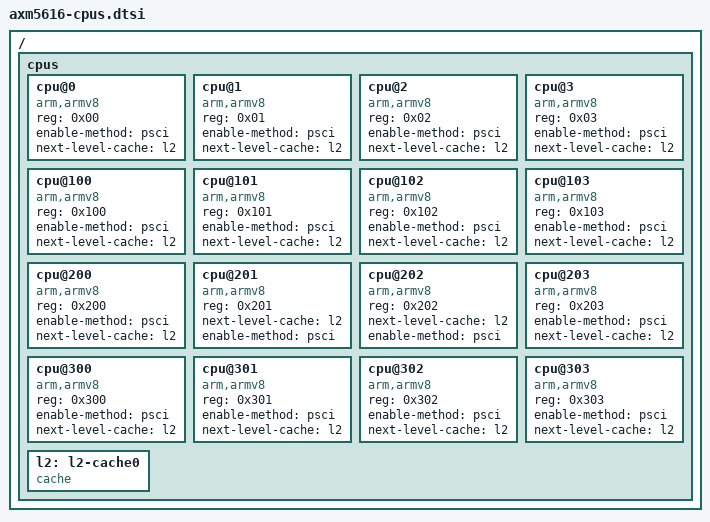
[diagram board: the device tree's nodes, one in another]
// SPDX-License-Identifier: GPL-2.0
// Copyright (C) 2021 INTEL Corporation

/ {
	cpus {
		#address-cells = <1>;
		#size-cells = <0>;

		cpu@0 {
			device_type = "cpu";
			compatible = "arm,armv8";
			reg = <0x00>;
			enable-method = "psci";
			next-level-cache = <&l2>;
		};

		cpu@1 {
			device_type = "cpu";
			compatible = "arm,armv8";
			reg = <0x01>;
			enable-method = "psci";
			next-level-cache = <&l2>;
		};

		cpu@2 {
			device_type = "cpu";
			compatible = "arm,armv8";
			reg = <0x02>;
			enable-method = "psci";
			next-level-cache = <&l2>;
		};

		cpu@3 {
			device_type = "cpu";
			compatible = "arm,armv8";
			reg = <0x03>;
			enable-method = "psci";
			next-level-cache = <&l2>;
		};

		cpu@100 {
			device_type = "cpu";
			compatible = "arm,armv8";
			reg = <0x100>;
			enable-method = "psci";
			next-level-cache = <&l2>;
		};

		cpu@101 {
			device_type = "cpu";
			compatible = "arm,armv8";
			reg = <0x101>;
			enable-method = "psci";
			next-level-cache = <&l2>;
		};

		cpu@102 {
			device_type = "cpu";
			compatible = "arm,armv8";
			reg = <0x102>;
			enable-method = "psci";
			next-level-cache = <&l2>;
		};

		cpu@103 {
			device_type = "cpu";
			compatible = "arm,armv8";
			reg = <0x103>;
			enable-method = "psci";
			next-level-cache = <&l2>;
		};

		cpu@200 {
			device_type = "cpu";
			compatible = "arm,armv8";
			reg = <0x200>;
			enable-method = "psci";
			next-level-cache = <&l2>;
		};

		cpu@201 {
			device_type = "cpu";
			compatible = "arm,armv8";
			reg = <0x201>;
			next-level-cache = <&l2>;
			enable-method = "psci";
		};

		cpu@202 {
			device_type = "cpu";
			compatible = "arm,armv8";
			reg = <0x202>;
			next-level-cache = <&l2>;
			enable-method = "psci";
		};

		cpu@203 {
			device_type = "cpu";
			compatible = "arm,armv8";
			reg = <0x203>;
			enable-method = "psci";
			next-level-cache = <&l2>;
		};

		cpu@300 {
			device_type = "cpu";
			compatible = "arm,armv8";
			reg = <0x300>;
			enable-method = "psci";
			next-level-cache = <&l2>;
		};

		cpu@301 {
			device_type = "cpu";
			compatible = "arm,armv8";
			reg = <0x301>;
			enable-method = "psci";
			next-level-cache = <&l2>;
		};

		cpu@302 {
			device_type = "cpu";
			compatible = "arm,armv8";
			reg = <0x302>;
			enable-method = "psci";
			next-level-cache = <&l2>;
		};

		cpu@303 {
			device_type = "cpu";
			compatible = "arm,armv8";
			reg = <0x303>;
			enable-method = "psci";
			next-level-cache = <&l2>;
		};

		l2: l2-cache0 {
			compatible = "cache";
		};
	};
};
